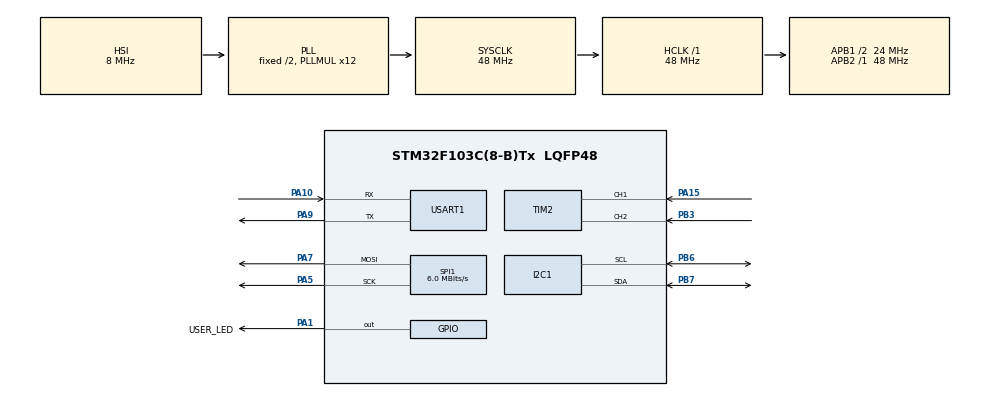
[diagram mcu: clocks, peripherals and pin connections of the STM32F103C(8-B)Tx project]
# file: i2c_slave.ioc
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I2C1.NoStretchMode=I2C_NOSTRETCH_DISABLE
I2C1.OwnAddress=0x12
Mcu.Family=STM32F1
Mcu.Name=STM32F103C(8-B)Tx
Mcu.Package=LQFP48
NVIC.I2C1_ER_IRQn=true\:0\:0\:false\:false\:true\:true\:true\:true
NVIC.I2C1_EV_IRQn=true\:0\:0\:false\:false\:true\:true\:true\:true
NVIC.PriorityGroup=NVIC_PRIORITYGROUP_4
NVIC.USART1_IRQn=true\:0\:0\:false\:false\:true\:true\:true\:true
PA1.GPIO_Label=USER_LED
PA1.Signal=GPIO_Output
PA10.Mode=Asynchronous
PA10.Signal=USART1_RX
PA13.Mode=Serial_Wire
PA13.Signal=SYS_JTMS-SWDIO
PA14.Mode=Serial_Wire
PA14.Signal=SYS_JTCK-SWCLK
PA15.Signal=S_TIM2_CH1_ETR
PA5.Mode=TX_Only_Simplex_Unidirect_Master
PA5.Signal=SPI1_SCK
PA7.Mode=TX_Only_Simplex_Unidirect_Master
PA7.Signal=SPI1_MOSI
PA9.Mode=Asynchronous
PA9.Signal=USART1_TX
PB3.Signal=S_TIM2_CH2
PB6.Mode=I2C
PB6.Signal=I2C1_SCL
PB7.Mode=I2C
PB7.Signal=I2C1_SDA
ProjectManager.HeapSize=0x200
ProjectManager.StackSize=0x400
ProjectManager.TargetToolchain=STM32CubeIDE
RCC.AHBFreq_Value=48000000
RCC.APB1CLKDivider=RCC_HCLK_DIV2
RCC.APB1Freq_Value=24000000
RCC.APB1TimFreq_Value=48000000
RCC.APB2Freq_Value=48000000
RCC.APB2TimFreq_Value=48000000
RCC.HCLKFreq_Value=48000000
RCC.PLLMUL=RCC_PLL_MUL12
RCC.SYSCLKFreq_VALUE=48000000
RCC.SYSCLKSource=RCC_SYSCLKSOURCE_PLLCLK
RCC.USBFreq_Value=48000000
SH.S_TIM2_CH1_ETR.0=TIM2_CH1,Encoder_Interface
SH.S_TIM2_CH2.0=TIM2_CH2,Encoder_Interface
SPI1.BaudRatePrescaler=SPI_BAUDRATEPRESCALER_8
SPI1.CalculateBaudRate=6.0 MBits/s
SPI1.Direction=SPI_DIRECTION_2LINES
SPI1.Mode=SPI_MODE_MASTER
SPI1.VirtualType=VM_MASTER
USART1.VirtualMode=VM_ASYNC
board=custom

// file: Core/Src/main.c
/* USER CODE BEGIN Header */
/**
  ******************************************************************************
  * @file           : main.c
  * @brief          : Main program body
  ******************************************************************************
  * @attention
  *
  * Copyright (c) 2024 STMicroelectronics.
  * All rights reserved.
  *
  * This software is licensed under terms that can be found in the LICENSE file
  * in the root directory of this software component.
  * If no LICENSE file comes with this software, it is provided AS-IS.
  *
  ******************************************************************************
  */
/* USER CODE END Header */
#include "main.h"

/* USER CODE BEGIN Includes */
#include <stdint.h>
#include "apps/main_task.h"
/* USER CODE END Includes */

I2C_HandleTypeDef hi2c1;

SPI_HandleTypeDef hspi1;

TIM_HandleTypeDef htim2;

void SystemClock_Config(void);
static void MX_GPIO_Init(void);
static void MX_I2C1_Init(void);
static void MX_USART1_UART_Init(void);
static void MX_SPI1_Init(void);
static void MX_TIM2_Init(void);

int main(void)
{

  /* MCU Configuration--------------------------------------------------------*/

  /* Reset of all peripherals, Initializes the Flash interface and the Systick. */
  HAL_Init();

  /* Configure the system clock */
  SystemClock_Config();

  /* Initialize all configured peripherals */
  MX_GPIO_Init();
  MX_I2C1_Init();
  MX_USART1_UART_Init();
  MX_SPI1_Init();
  MX_TIM2_Init();
  /* USER CODE BEGIN 2 */
  if (HAL_I2C_EnableListen_IT(&hi2c1) != HAL_OK)
  {
    Error_Handler();
  }

  main_task_init();

  /* USER CODE END 2 */

  /* Infinite loop */
  while (1)
  {

    /* USER CODE BEGIN 3 */
	  main_task_run(NULL);

  }
  /* USER CODE END 3 */
}

void SystemClock_Config(void)
{
  RCC_OscInitTypeDef RCC_OscInitStruct = {0};
  RCC_ClkInitTypeDef RCC_ClkInitStruct = {0};

  /** Initializes the RCC Oscillators according to the specified parameters
  * in the RCC_OscInitTypeDef structure.
  */
  RCC_OscInitStruct.OscillatorType = RCC_OSCILLATORTYPE_HSI;
  RCC_OscInitStruct.HSIState = RCC_HSI_ON;
  RCC_OscInitStruct.HSICalibrationValue = RCC_HSICALIBRATION_DEFAULT;
  RCC_OscInitStruct.PLL.PLLState = RCC_PLL_ON;
  RCC_OscInitStruct.PLL.PLLSource = RCC_PLLSOURCE_HSI_DIV2;
  RCC_OscInitStruct.PLL.PLLMUL = RCC_PLL_MUL12;
  if (HAL_RCC_OscConfig(&RCC_OscInitStruct) != HAL_OK)
  {
    Error_Handler();
  }

  /** Initializes the CPU, AHB and APB buses clocks
  */
  RCC_ClkInitStruct.ClockType = RCC_CLOCKTYPE_HCLK|RCC_CLOCKTYPE_SYSCLK
                              |RCC_CLOCKTYPE_PCLK1|RCC_CLOCKTYPE_PCLK2;
  RCC_ClkInitStruct.SYSCLKSource = RCC_SYSCLKSOURCE_PLLCLK;
  RCC_ClkInitStruct.AHBCLKDivider = RCC_SYSCLK_DIV1;
  RCC_ClkInitStruct.APB1CLKDivider = RCC_HCLK_DIV2;
  RCC_ClkInitStruct.APB2CLKDivider = RCC_HCLK_DIV1;

  if (HAL_RCC_ClockConfig(&RCC_ClkInitStruct, FLASH_LATENCY_1) != HAL_OK)
  {
    Error_Handler();
  }
}

static void MX_I2C1_Init(void)
{

  hi2c1.Instance = I2C1;
  hi2c1.Init.ClockSpeed = 100000;
  hi2c1.Init.DutyCycle = I2C_DUTYCYCLE_2;
  hi2c1.Init.OwnAddress1 = 36;
  hi2c1.Init.AddressingMode = I2C_ADDRESSINGMODE_7BIT;
  hi2c1.Init.DualAddressMode = I2C_DUALADDRESS_DISABLE;
  hi2c1.Init.OwnAddress2 = 0;
  hi2c1.Init.GeneralCallMode = I2C_GENERALCALL_DISABLE;
  hi2c1.Init.NoStretchMode = I2C_NOSTRETCH_DISABLE;
  if (HAL_I2C_Init(&hi2c1) != HAL_OK)
  {
    Error_Handler();
  }

}

static void MX_SPI1_Init(void)
{

  /* SPI1 parameter configuration*/
  hspi1.Instance = SPI1;
  hspi1.Init.Mode = SPI_MODE_MASTER;
  hspi1.Init.Direction = SPI_DIRECTION_2LINES;
  hspi1.Init.DataSize = SPI_DATASIZE_8BIT;
  hspi1.Init.CLKPolarity = SPI_POLARITY_LOW;
  hspi1.Init.CLKPhase = SPI_PHASE_1EDGE;
  hspi1.Init.NSS = SPI_NSS_SOFT;
  hspi1.Init.BaudRatePrescaler = SPI_BAUDRATEPRESCALER_8;
  hspi1.Init.FirstBit = SPI_FIRSTBIT_MSB;
  hspi1.Init.TIMode = SPI_TIMODE_DISABLE;
  hspi1.Init.CRCCalculation = SPI_CRCCALCULATION_DISABLE;
  hspi1.Init.CRCPolynomial = 10;
  if (HAL_SPI_Init(&hspi1) != HAL_OK)
  {
    Error_Handler();
  }

}

static void MX_TIM2_Init(void)
{

  TIM_Encoder_InitTypeDef sConfig = {0};
  TIM_MasterConfigTypeDef sMasterConfig = {0};

  htim2.Instance = TIM2;
  htim2.Init.Prescaler = 0;
  htim2.Init.CounterMode = TIM_COUNTERMODE_UP;
  htim2.Init.Period = 65535;
  htim2.Init.ClockDivision = TIM_CLOCKDIVISION_DIV1;
  htim2.Init.AutoReloadPreload = TIM_AUTORELOAD_PRELOAD_DISABLE;
  sConfig.EncoderMode = TIM_ENCODERMODE_TI1;
  sConfig.IC1Polarity = TIM_ICPOLARITY_RISING;
  sConfig.IC1Selection = TIM_ICSELECTION_DIRECTTI;
  sConfig.IC1Prescaler = TIM_ICPSC_DIV1;
  sConfig.IC1Filter = 0;
  sConfig.IC2Polarity = TIM_ICPOLARITY_RISING;
  sConfig.IC2Selection = TIM_ICSELECTION_DIRECTTI;
  sConfig.IC2Prescaler = TIM_ICPSC_DIV1;
  sConfig.IC2Filter = 0;
  if (HAL_TIM_Encoder_Init(&htim2, &sConfig) != HAL_OK)
  {
    Error_Handler();
  }
  sMasterConfig.MasterOutputTrigger = TIM_TRGO_RESET;
  sMasterConfig.MasterSlaveMode = TIM_MASTERSLAVEMODE_DISABLE;
  if (HAL_TIMEx_MasterConfigSynchronization(&htim2, &sMasterConfig) != HAL_OK)
  {
    Error_Handler();
  }

}

static void MX_USART1_UART_Init(void)
{

  LL_USART_InitTypeDef USART_InitStruct = {0};

  LL_GPIO_InitTypeDef GPIO_InitStruct = {0};

  /* Peripheral clock enable */
  LL_APB2_GRP1_EnableClock(LL_APB2_GRP1_PERIPH_USART1);

  LL_APB2_GRP1_EnableClock(LL_APB2_GRP1_PERIPH_GPIOA);
  /**USART1 GPIO Configuration
  PA9   ------> USART1_TX
  PA10   ------> USART1_RX
  */
  GPIO_InitStruct.Pin = LL_GPIO_PIN_9;
  GPIO_InitStruct.Mode = LL_GPIO_MODE_ALTERNATE;
  GPIO_InitStruct.Speed = LL_GPIO_SPEED_FREQ_HIGH;
  GPIO_InitStruct.OutputType = LL_GPIO_OUTPUT_PUSHPULL;
  LL_GPIO_Init(GPIOA, &GPIO_InitStruct);

  GPIO_InitStruct.Pin = LL_GPIO_PIN_10;
  GPIO_InitStruct.Mode = LL_GPIO_MODE_FLOATING;
  LL_GPIO_Init(GPIOA, &GPIO_InitStruct);

  /* USART1 interrupt Init */
  NVIC_SetPriority(USART1_IRQn, NVIC_EncodePriority(NVIC_GetPriorityGrouping(),0, 0));
  NVIC_EnableIRQ(USART1_IRQn);

  USART_InitStruct.BaudRate = 115200;
  USART_InitStruct.DataWidth = LL_USART_DATAWIDTH_8B;
  USART_InitStruct.StopBits = LL_USART_STOPBITS_1;
  USART_InitStruct.Parity = LL_USART_PARITY_NONE;
  USART_InitStruct.TransferDirection = LL_USART_DIRECTION_TX_RX;
  USART_InitStruct.HardwareFlowControl = LL_USART_HWCONTROL_NONE;
  USART_InitStruct.OverSampling = LL_USART_OVERSAMPLING_16;
  LL_USART_Init(USART1, &USART_InitStruct);
  LL_USART_ConfigAsyncMode(USART1);
  LL_USART_Enable(USART1);

}

static void MX_GPIO_Init(void)
{
  GPIO_InitTypeDef GPIO_InitStruct = {0};

  /* GPIO Ports Clock Enable */
  __HAL_RCC_GPIOA_CLK_ENABLE();
  __HAL_RCC_GPIOB_CLK_ENABLE();

  /*Configure GPIO pin Output Level */
  HAL_GPIO_WritePin(USER_LED_GPIO_Port, USER_LED_Pin, GPIO_PIN_RESET);

  /*Configure GPIO pin : USER_LED_Pin */
  GPIO_InitStruct.Pin = USER_LED_Pin;
  GPIO_InitStruct.Mode = GPIO_MODE_OUTPUT_PP;
  GPIO_InitStruct.Pull = GPIO_NOPULL;
  GPIO_InitStruct.Speed = GPIO_SPEED_FREQ_LOW;
  HAL_GPIO_Init(USER_LED_GPIO_Port, &GPIO_InitStruct);

}

void Error_Handler(void)
{
  /* USER CODE BEGIN Error_Handler_Debug */
  /* User can add his own implementation to report the HAL error return state */
//  __disable_irq();
//  while (1)
//  {
//  }
  /* USER CODE END Error_Handler_Debug */
}
